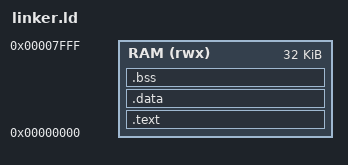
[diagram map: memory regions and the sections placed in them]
ENTRY(_start)

MEMORY
{
    RAM (rwx) : ORIGIN = 0x00000000, LENGTH = 32K
}

_stack_top = ORIGIN(RAM) + LENGTH(RAM);

SECTIONS
{
    .text : {
        *(.text*)
        *(.rodata*)
    } > RAM

    .data : {
        *(.data*)
    } > RAM

    .bss : {
        *(.bss*)
        *(COMMON)
    } > RAM
}
